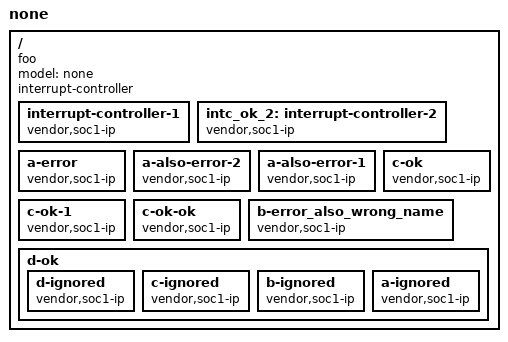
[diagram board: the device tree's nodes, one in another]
// SPDX-License-Identifier: BSD-2-Clause
/dts-v1/;
/ {
	model = "none";
	compatible = "foo";

	#address-cells = <1>;
	#size-cells = <1>;

	interrupt-controller;
	#interrupt-cells = <1>;

	interrupt-controller-1 {
		compatible = "vendor,soc1-ip";
	};

	intc_ok_2: interrupt-controller-2 {
		compatible = "vendor,soc1-ip";
	};

	a-error {
		compatible = "vendor,soc1-ip";
	};

	a-also-error-2 { // Comment
		compatible = "vendor,soc1-ip";
	};

	a-also-error-1 { /* Comment */
		compatible = "vendor,soc1-ip";
	};

	c-ok {
		compatible = "vendor,soc1-ip";
	};

	c-ok-1 { // Comment
		compatible = "vendor,soc1-ip";
	};

	c-ok-ok { /* Comment */
		compatible = "vendor,soc1-ip";
	};

	b-error_also_wrong_name {
		compatible = "vendor,soc1-ip";
	};

	d-ok {
		d-ignored {
			compatible = "vendor,soc1-ip";
		};

		c-ignored {
			compatible = "vendor,soc1-ip";
		};

		b-ignored { // Comment
			compatible = "vendor,soc1-ip";
		};

		a-ignored { /* Comment */
			compatible = "vendor,soc1-ip";
		};
	}
};
